# CEC1702 register map
Vendor: Microchip Technology; Series: CEC1702Q; File version: 0
CPU: CM4 r1p0, little endian, MPU, FPU, 3 interrupt priority bits, 155 interrupts
Registers are 32-bit, read-write, reset 0x0 unless marked. A register's access mark holds for its fields unless they carry their own. Offsets are from the block's base; [hi:lo] are bit positions.

## FAN0 — The RPM-PWM Interface is an RPM based Fan Control Algorithm that monitors the fan's speed and automatically adjusts the drive to maintain the desired fan speed. This RPM based Fan Control Algorithm controls a PWM output based on a tachometer input.
Base 0x4000A000; register names take the prefix FAN_
Same registers: FAN1 0x4000A080
0x00 SET 16-bit — The Fan Driver Setting used to control the output of the Fan Driver.
  [15:6] FAN_SETTING
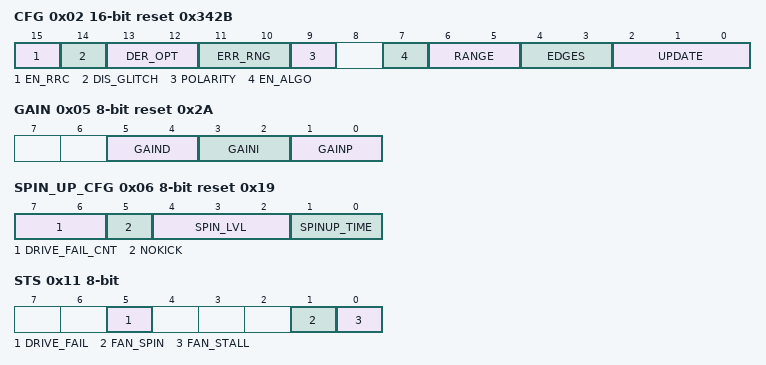
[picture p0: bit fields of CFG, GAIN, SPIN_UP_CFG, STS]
0x02 CFG 16-bit reset 0x342B — The Fan Configuration Register controls the general operation of the RPM based Fan Control Algorithm used by the fan driver.
  [15] EN_RRC — Enables the ramp rate control circuitry during the Manual Mode of operation. 1=The ramp rate control circuitry for the Manual Mode of operation is enabled. The PWM setting will follow the ramp rate controls as determined by the Fan Step and Update Time settings. The maximum PWM step is capped at the Fan Step setting and is updated based on the Update Time as given by the field UPDATE. 0=The ramp rate control circuitry for the Manual Mode of operation is disabled. When the Fan Drive Setting values are changed and the RPM based Fan Control Algorithm is disabled, the fan driver will be set to the new setting immediately.
  [14] DIS_GLITCH — Disables the low pass glitch filter that removes high frequency noise injected on the TACH pin. 1 - The glitch filter is disabled. 0 - The glitch filter is enabled.
  [13:12] DER_OPT — Control some of the advanced options that affect the derivative portion of the RPM based fan control algorithm. These bits only apply if the Fan Speed Control Algorithm is used.
  [11:10] ERR_RNG — Control some of the advanced options that affect the error window. When the measured fan speed is within the programmed error window around the target speed, the fan drive setting is not updated. These bits only apply if the Fan Speed Control Algorithm is used. 3=200 RPM. 2=100 RPM. 1=50 RPM. 0=0 RPM
    3=RPM_200 (3=200 RPM); 2=RPM_100 (2=100 RPM); 1=RPM_50 (1=50 RPM); 0=RPM_0 (0=0 RPM)
  [9] POLARITY — Determines the polarity of the PWM driver. This does NOT affect the drive setting registers. A setting of 0% drive will still correspond to 0% drive independent of the polarity. 1 - The Polarity of the PWM driver is inverted. A drive setting of 00h will cause the output to be set at 100% duty cycle and a drive setting of FFh will cause the output to be set at 0% duty cycle. 0 - the Polarity of the PWM driver is normal. A drive setting of 00h will cause the output to be set at 0% duty cycle and a drive setting of FFh will cause the output to be set at 100% duty cycle.
  [7] EN_ALGO — Enables the RPM based Fan Control Algorithm. 1=The control circuitry is enabled and the Fan Driver output will be automatically updated to maintain the programmed fan speed as indicated by the TACH Target Register. 0=The control circuitry is disabled and the fan driver output is determined by the Fan Driver Setting Register.
  [6:5] RANGE — Adjusts the range of reported and programmed tachometer reading values. The RANGE bits determine the weighting of all. TACH values (including the Valid TACH Count, TACH Target, and TACH reading). 3=Reported Minimum RPM: 4000. Tach Count Multiplier: 1. 2=Reported Minimum RPM: 2000. Tach Count Multiplier: 2. 1=Reported Minimum RPM: 1000. Tach Count Multiplier: 4. 0=Reported Minimum RPM: 500. Tach Count Multiplier: 8
    3=TACH_COUNT_MULTIPLIER_8 (3=Reported Minimum RPM: 4000. Tach Count Multiplier: 8); 2=TACH_COUNT_MULTIPLIER_4 (2=Reported Minimum RPM: 2000. Tach Count Multiplier: 4); 1=TACH_COUNT_MULTIPLIER_2 (1=Reported Minimum RPM: 1000. Tach Count Multiplier: 2); 0=TACH_COUNT_MULTIPLIER_1 (0=Reported Minimum RPM: 500. Tach Count Multiplier: 1)
  [4:3] EDGES — Determines the minimum number of edges that must be detected on the TACH signal to determine a single rotation. A typical fan measured 5 edges (for a 2-pole fan). Increasing the number of edges measured with respect to the number of poles of the fan will cause the TACH Reading registers to indicate a fan speed that is higher or lower than the actual speed. In order for the FSC Algorithm to operate correctly, the TACH Target must be updated by the user to accommodate this shift. The Effective Tach Multiplier is used as a direct multiplier term that is applied to the Actual RPM to achieve the Reported RPM. It should only be applied if the number of edges measured does not match the number of edges expected based on the number of poles of the fan (which is fixed for any given fan).
  [2:0] UPDATE — Determines the base time between fan driver updates. The Update Time, along with the Fan Step Register, is used to control the ramp rate of the drive response to provide a cleaner transition of the actual fan operation as the desired fan speed changes. 7=1600ms. 6=1200ms. 5=800ms. 4=500ms. 3=400ms. 2=300ms. 1=200ms. 0=100ms. Note: This ramp rate control applies for all changes to the active PWM output including when the RPM based Fan Speed Control Algorithm is disabled.
    7=BASE_TIME_1600ms (7=1600ms); 6=BASE_TIME_1200ms (6=1200ms); 6=BASE_TIME_800ms (5=800ms); 5=BASE_TIME_500ms (4=500ms); 4=BASE_TIME_400ms (3=400ms); 3=BASE_TIME_300ms (2=300ms); 2=BASE_TIME_200ms (1=200ms); 1=BASE_TIME_100ms (0=100ms)
0x04 PWM_DIV 8-bit reset 0x1 — PWM Divide
  [7:0] PWM_DIV — The PWM Divide value determines the final frequency of the PWM driver. The driver base frequency is divided by the. PWM Divide value to determine the final frequency.
0x05 GAIN 8-bit reset 0x2A — Gain Register stores the gain terms used by the proportional and integral portions of the RPM based Fan Control Algorithm.
  [5:4] GAIND — The derivative gain term. Gain Factor: 3=8x. 2=4x. 1=2x. 0=1x
    3=GAIND_8X (Gain Factor: 3=8x); 2=GAIND_4X (Gain Factor: 2=4x); 1=GAIND_2X (Gain Factor: 1=2x); 0=GAIND_1X (Gain Factor: 0=1x)
  [3:2] GAINI — The integral gain term. Gain Factor: 3=8x. 2=4x. 1=2x. 0=1x
    3=GAINI_8X (Gain Factor: 3=8x); 2=GAINI_4X (Gain Factor: 2=4x); 1=GAINI_2X (Gain Factor: 1=2x); 0=GAINI_1X (Gain Factor: 0=1x)
  [1:0] GAINP — The proportional gain term. Gain Factor: 3=8x. 2=4x. 1=2x. 0=1x
    3=GAINP_8X (Gain Factor: 3=8x); 2=GAINP_4X (Gain Factor: 2=4x); 1=GAINP_2X (Gain Factor: 1=2x); 0=GAINP_1X (Gain Factor: 0=1x)
0x06 SPIN_UP_CFG 8-bit reset 0x19 — The Fan Spin Up Configuration Register controls the settings of Spin Up Routine.
  [7:6] DRIVE_FAIL_CNT — Determines how many update cycles are used for the Drive Fail detection function. This circuitry determines whether the fan can be driven to the desired Tach target. These settings only apply if the Fan Speed Control Algorithm is enabled. 3=Drive Fail detection circuitry will count for 64 update periods. 2=Drive Fail detection circuitry will count for 32 update periods. 1=Drive Fail detection circuitry will count for 16 update periods. 0=Drive Fail detection circuitry is disabled.
    3=DRIVE_FAIL_CNT_64_PERIOD (3=Drive Fail detection circuitry will count for 64 update periods); 2=DRIVE_FAIL_CNT_32_PERIOD (2=Drive Fail detection circuitry will count for 32 update periods); 1=DRIVE_FAIL_CNT_16_PERIOD (1=Drive Fail detection circuitry will count for 16 update periods); 0=DRIVE_FAIL_CNT_DIS (0=Drive Fail detection circuitry is disabled.)
  [5] NOKICK — Determines if the Spin Up Routine will drive the fan to 100% duty cycle for 1/4 of the programmed spin up time before driving it at the programmed level. 1=The Spin Up Routine will not drive the PWM to 100%. It will set the drive at the programmed spin level for the entire duration of the programmed spin up time. 0=The Spin Up Routine will drive the PWM to 100% for 1/4 of the programmed spin up time before reverting to the programmed spin level.
  [4:2] SPIN_LVL — Determines the final drive level that is used by the Spin Up Routine. 7=65% 6=60% 5=55% 4=50% 3=45% 2=40% 1=35% 0=30%
    7=7=65%; 6=6=60%; 5=5=55%; 4=4=50%; 3=3=45%; 2=2=40%; 1=1=35%; 0=0=30%
  [1:0] SPINUP_TIME — Determines the maximum Spin Time that the Spin Up Routine will run for. If a valid tachometer measurement is not detected before the Spin Time has elapsed, an interrupt will be generated. When the RPM based Fan Control Algorithm is active, the fan driver will attempt to re-start the fan immediately after the end of the last spin up attempt. 3=2 seconds. 2=1 second. 1=500 ms. 0=250 ms
    3=SPINUP_2_SEC (3=2 seconds); 2=SPINUP_1_SEC (2=1 second); 1=SPINUP_500_MSEC (1=500 ms); 0=SPINUP_250_MSEC (0=250 ms)
0x07 STEP 8-bit reset 0x10 — FAN_STEP The Fan Step value represents the maximum step size the fan driver will take between update times
  [7:0] FAN_STEP — The Fan Step value represents the maximum step size the fan driver will take between update times. When the PWM_BASE frequency range field in the PWM Driver Base Frequency Register is set to the value 1, 2 or 3, this 8-bit field is added to the 10-bit PWM duty cycle, for a maximum step size of 25%. When the PWM_BASE field is set to 0, the PWM operates in an 8-bit mode. In 8-bit mode, this 8-bit field is added to the 8-bit duty cycle, for a maximum step size of 100%.
0x08 MIN_DRIVE 8-bit reset 0x66 — the minimum drive setting for the RPM based Fan Control Algorithm.
  [7:0] MIN_DRIVE — The minimum drive setting.
0x09 VAL_TACH_CNT 8-bit reset 0xF5 — The maximum TACH Reading Register value to indicate that the fan is spinning properly.
  [7:0] VALID_TACH_CNT
0x0A DRIVE_FAIL_BAND 16-bit — The number of Tach counts used by the Fan Drive Fail detection circuitry
  [15:3] FAN_DRIVE_FAIL_BAND — The number of Tach counts used by the Fan Drive Fail detection circuitry.
0x0C TACH_TGT 16-bit — The target tachometer value.
  [15:3] TACH_TGT
0x0E TACH_RD 16-bit — [15:3] The current tachometer reading value.
  [15:3] TACH_RD — The current tachometer reading value.
0x10 DRIV_BASE_FREQ 8-bit — [1:0] Determines the frequency range of the PWM fan driver
  [1:0] PWM_BASE — Determines the frequency range of the PWM fan driver (when enabled). PWM resolution is 10-bit, except when this field is set to '0b', when it is 8-bit. 3=2.34KHz. 2=4.67KHz. 1=23.4KHz. 0=26.8KHz
    3=PWM_FAN_FREQ_2KHZ (3=2.34KHz); 2=PWM_FAN_FREQ_4KHZ (2=4.67KHz); 1=PWM_FAN_FREQ_23KHZ (1=23.4KHz); 0=PWM_FAN_FREQ_26KHZ (0=26.8KHz)
0x11 STS 8-bit — The bits in this register are routed to interrupts.
  [5] DRIVE_FAIL — The bit Indicates that the RPM-based Fan Speed Control Algorithm cannot drive the Fan to the desired target setting at maximum drive. (R/WC). 1- The RPM-based Fan Speed Control Algorithm cannot drive Fan to the desired target setting at maximum drive. 0- The RPM-based Fan Speed Control Algorithm can drive Fan to the desired target setting.
  [1] FAN_SPIN — The bit Indicates that the Spin up Routine for the Fan could not detect a valid tachometer reading within its maximum time window. (R/WC). 1 - The Spin up Routine for the Fan could not detect a valid tachometer reading within its maximum time window. 0 - The Spin up Routine for the Fan detected a valid tachometer reading within its maximum time window.
  [0] FAN_STALL — The bit Indicates that the tachometer measurement on the Fan detects a stalled fan. (R/WC). 0 - Stalled fan not detected. 1 - Stalled fan detected.
